# MIMXRT685S_cm33 register map
Vendor: nxp.com; File version: 1.0
CPU: CM33 r2p0, little endian, MPU, FPU, VTOR, 3 interrupt priority bits
Registers are 32-bit, read-write, reset 0x0 unless marked. A register's access mark holds for its fields unless they carry their own. Offsets are from the block's base; [hi:lo] are bit positions; lines under a group give offsets from that group; {n}, {i} and the like mark numbered series; 'fields as' and 'values as' point back to an identical list.

## CLKCTL1 — clock ccontroller 1
Base 0x40021000
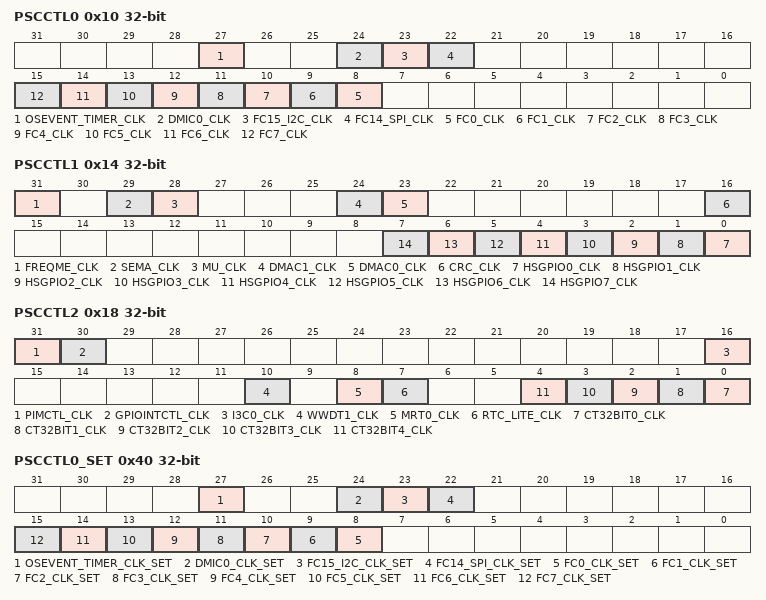
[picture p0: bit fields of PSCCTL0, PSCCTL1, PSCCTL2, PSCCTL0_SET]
0x10 PSCCTL0 — clock control register 0
  [all] fields
    0=DISABLE_CLOCK; 1=ENABLE_CLOCK
  [27] OSEVENT_TIMER_CLK — OS event timer clock control
  [24] DMIC0_CLK — DMIC0 clock control
  [23] FC15_I2C_CLK — flexcomm 15 i2c clock control
  [22] FC14_SPI_CLK — flexcomm 14 spi clock control
  [n+8] FC{n}_CLK (n=0..7) — flexcomm {n} clock control
0x14 PSCCTL1 — clock control register 1
  [all] fields
    0=DISABLE_CLOCK; 1=ENABLE_CLOCK
  [31] FREQME_CLK — FREQME clock control
  [29] SEMA_CLK — SEMA clock control
  [28] MU_CLK — MU clock control
  [24] DMAC1_CLK — DMAC1 clock control
  [23] DMAC0_CLK — DMAC0 clock control
  [16] CRC_CLK — CRC clock control
  [n] HSGPIO{n}_CLK (n=0..7) — HSGPIO{n} clock control
0x18 PSCCTL2 — clock control register 2
  [all] fields
    0=DISABLE_CLOCK; 1=ENABLE_CLOCK
  [31] PIMCTL_CLK — PIMCTL clock control
  [30] GPIOINTCTL_CLK — GPIOINTCTL clock control
  [16] I3C0_CLK — i3c0 clock control
  [10] WWDT1_CLK — wdt1 clock control
  [8] MRT0_CLK — mrt0 clock control
  [7] RTC_LITE_CLK — rtc lite clock control
  [n] CT32BIT{n}_CLK (n=0..4) — ct32bit timer {n} clock control
0x40 PSCCTL0_SET wo reset not defined — clock set register 0
  [all] fields
    0=NO_EFFECT; 1=SET_CLOCK (Sets the PSCCTL0 Bit)
  [27] OSEVENT_TIMER_CLK_SET — OS event timer clock set
  [24] DMIC0_CLK_SET — DMIC0 clock set
  [23] FC15_I2C_CLK_SET — flexcomm 15 i2c clock set
  [22] FC14_SPI_CLK_SET — flexcomm 14 spi clock set
  [n+8] FC{n}_CLK_SET (n=0..7) — flexcomm {n} clock set
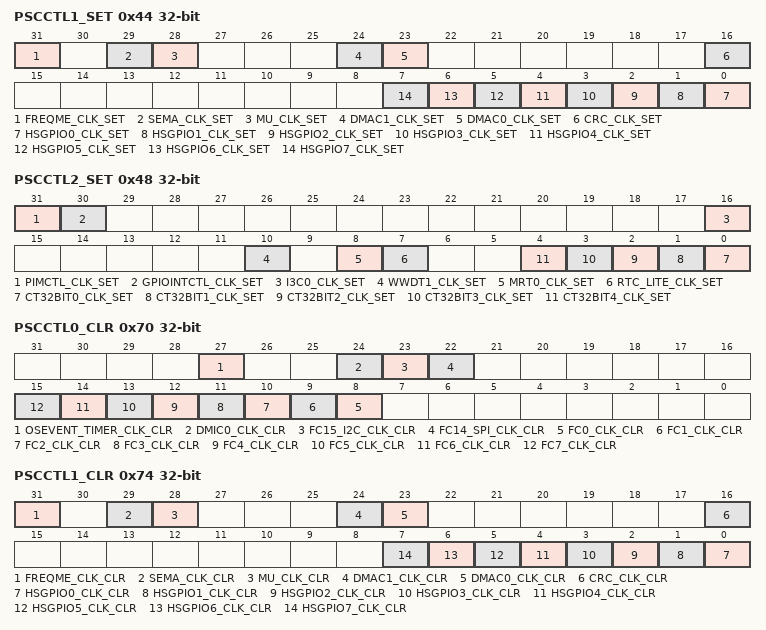
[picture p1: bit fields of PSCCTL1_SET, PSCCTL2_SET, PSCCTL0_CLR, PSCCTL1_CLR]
0x44 PSCCTL1_SET wo reset not defined — clock set register 1
  [all] fields
    0=NO_EFFECT; 1=SET_CLOCK (Sets the PSCCTL1 Bit)
  [31] FREQME_CLK_SET — FREQME clock set
  [29] SEMA_CLK_SET — SEMA clock set
  [28] MU_CLK_SET — MU clock set
  [24] DMAC1_CLK_SET — DMAC1 clock set
  [23] DMAC0_CLK_SET — DMAC0 clock set
  [16] CRC_CLK_SET — CRC clock set
  [n] HSGPIO{n}_CLK_SET (n=0..7) — HSGPIO{n} clock set
0x48 PSCCTL2_SET wo reset not defined — clock set register 2
  [all] fields
    0=NO_EFFECT; 1=SET_CLOCK (Sets the PSCCTL2 Bit)
  [31] PIMCTL_CLK_SET — PIMCTL clock set
  [30] GPIOINTCTL_CLK_SET — GPIOINTCTL clock set
  [16] I3C0_CLK_SET — i3c0 clock set
  [10] WWDT1_CLK_SET — wdt1 clock set
  [8] MRT0_CLK_SET — mrt0 clock set
  [7] RTC_LITE_CLK_SET — rtc lite clock set
  [n] CT32BIT{n}_CLK_SET (n=0..4) — ct32bit timer {n} clock set
0x70 PSCCTL0_CLR wo reset not defined — clock clear register 0
  [all] fields
    0=NO_EFFECT; 1=CLR_CLOCK (Clears the PSCCTL0 Bit)
  [27] OSEVENT_TIMER_CLK_CLR — OS event timer clock clear
  [24] DMIC0_CLK_CLR — DMIC0 clock set
  [23] FC15_I2C_CLK_CLR — flexcomm 15 i2c clock clear
  [22] FC14_SPI_CLK_CLR — flexcomm 14 spi clock clear
  [n+8] FC{n}_CLK_CLR (n=0..7) — flexcomm {n} clock clear
0x74 PSCCTL1_CLR wo reset not defined — clock clear register 1
  [all] fields
    0=NO_EFFECT; 1=CLR_CLOCK (Clears the PSCCTL1 Bit)
  [31] FREQME_CLK_CLR — FREQME clock clear
  [29] SEMA_CLK_CLR — SEMA clock clear
  [28] MU_CLK_CLR — MU clock clear
  [24] DMAC1_CLK_CLR — DMAC1 clock clear
  [23] DMAC0_CLK_CLR — DMAC0 clock clear
  [16] CRC_CLK_CLR — CRC clock clear
  [n] HSGPIO{n}_CLK_CLR (n=0..7) — HSGPIO{n} clock clear
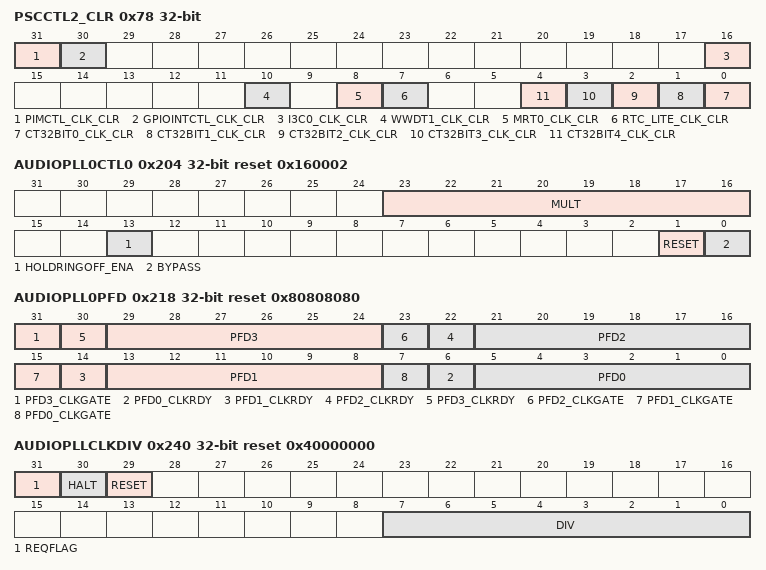
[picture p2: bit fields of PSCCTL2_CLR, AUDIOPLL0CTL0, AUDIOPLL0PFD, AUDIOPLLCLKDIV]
0x78 PSCCTL2_CLR wo reset not defined — clock clear register 2
  [all] fields
    0=NO_EFFECT; 1=CLR_CLOCK (Clears the PSCCTL2 Bit)
  [31] PIMCTL_CLK_CLR — PIMCTL clock clear
  [30] GPIOINTCTL_CLK_CLR — GPIOINTCTL clock clear
  [16] I3C0_CLK_CLR — i3c0 clock clear
  [10] WWDT1_CLK_CLR — wdt1 clock clear
  [8] MRT0_CLK_CLR — mrt0 clock clear
  [7] RTC_LITE_CLK_CLR — rtc lite clock clear
  [n] CT32BIT{n}_CLK_CLR (n=0..4) — ct32bit timer {n} clock clear
0x200 AUDIOPLL0CLKSEL reset 0x7 — audio pll0 clock selection
  [2:0] SEL — System PLL Clock Source Selection. . .
    0=SFRO_CLK (SFRO Clock.); 1=XTAL_CLK (XTALIN Clock.); 2=FFRO_DIV_2 (FFRO Clock Divided by 2.); 7=NONE (None, this may be selected in order to reduce power when no output is needed.)
0x204 AUDIOPLL0CTL0 reset 0x160002 — audio pll0 control0
  [23:16] MULT — Multiplication Factor for FAUDIOPLL0_OUTPUT:
    16=DIV_16; 17=DIV_17; 20=DIV_20; 22=DIV_22; 27=DIV_27; 33=DIV_33
  [13] HOLDRINGOFF_ENA — Hold Ring Off Control
    0=DSIABLE (disbale); 1=ENABLE
  [1] RESET — AUDIOPLL0 Reset:
    0=NORMAL (AUDIOPLL0 reset is removed.); 1=RESET (AUDIOPLL0 is placed into reset.)
  [0] BYPASS — AUDIOPLL0 BYPASS Mode
    0=PROGRAMMED_CLK (PFD output is PFD programmed clock.); 1=BYPASS (PFD output is AUDIOPLL0 reference input clock. (Bypass Mode))
0x20C AUDIOPLL0LOCKTIMEDIV2 reset 0xCAFE — audio pll0 lock time
  [15:0] LOCKTIMEDIV2 — AUDIOPLL0 Lock Time Divide by 2: Programmed lock time is in uS (micro-seconds) and is programmed as half the actual lock time value.
0x210 AUDIOPLL0NUM reset 0x4DD2F15 — audio pll0 number
  [29:0] NUM — This field contains the numerator of the AUDIOPLL0 fractional loop divider. NOTES: 1. The value of numerator must always be configured to be less than the value of the denominator. 2. The AUDIOPLL0NUM register can only be changed when the AUDIOPLL0 is disabled.
0x214 AUDIOPLL0DENOM reset 0x1FFFFFDB
  [29:0] DENOM — This field contains the denominator of the AUDIOPLL0 fractional loop divider. NOTES: 1. The value of numerator must always be configured to be less than the value of the denominator. 2. The AUDIOPLL0DENOM register can only be changed when the AUDIOPLL0 is disabled.
0x218 AUDIOPLL0PFD reset 0x80808080
  [31] PFD3_CLKGATE — PFD3 Clock Gate: 0: PFD3 clock is not gated. 1: PFD3 clock is gated.
    0=NOT_GATED (PFD3 clock is not gated.); 1=GATED (PFD3 clock is gated.)
  [8n+6] PFD{n}_CLKRDY (n=0..3) — PFD{n} Clock Ready Status Flag: Read as 1 clock ready. Cleared by writing a 1.
  [8n+5:8n] PFD{n} (n=0..3) — PLL Fractional Divider {n}: Controls the fractional divider value. Valid PFD values are decimal 12-35.
  [23] PFD2_CLKGATE — PFD2 Clock Gate: 0: PFD2 clock is not gated. 1: PFD2 clock is gated.
    0=NOT_GATED (PFD2 clock is not gated.); 1=GATED (PFD2 clock is gated.)
  [15] PFD1_CLKGATE — PFD1 Clock Gate: 0: PFD1 clock is not gated. 1: PFD1 clock is gated.
    0=NOT_GATED (PFD1 clock is not gated.); 1=GATED (PFD1 clock is gated.)
  [7] PFD0_CLKGATE — PFD0 Clock Gate: 0: PFD0 clock is not gated. 1: PFD0 clock is gated
    0=NOT_GATED (PFD0 clock is not gated.); 1=GATED (PFD0 clock is gated.)
0x240 AUDIOPLLCLKDIV reset 0x40000000 — audio pll0 clock divider
  [31] REQFLAG — Divider status flag. Set when a change is made to the divider value, cleared when the change is complete.
  [30] HALT — Halts the divider counter. The intent is to allow the divider's clock source to be changed without the risk of a glitch at the output.
  [29] RESET — Resets the divider counter. Can be used to make sure a new divider value is used right away rather than completing the previous count.
  [7:0] DIV — Clock Divider Value Selection. . . 0: Divide by 1. ... 255: Divide by 256.
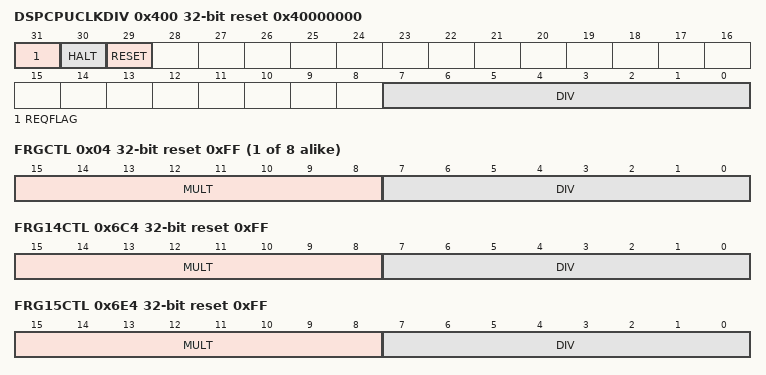
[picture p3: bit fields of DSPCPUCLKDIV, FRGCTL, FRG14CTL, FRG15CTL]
0x400 DSPCPUCLKDIV reset 0x40000000 — DSP cpu clock divider
  fields as AUDIOPLLCLKDIV
0x404 DSPMAINRAMCLKDIV reset 0x1 — DSP main ram clock divider
  [1:0] DSPMRAMCLKDIV — DSP MAINRAM Clock Ratio Control:
    {v}=DSP_CLK_DIV_BY_{v+1} (DSP MAINRAM Clk = DSP Core CLK / {v+1}.) (v=0..3)
0x430 DSPCPUCLKSELA — DSP clock selection A
  [1:0] SEL — Control Main 1st Stage Control Clock Source. . .
    0=FFRO_CLK (FFRO Clock.); 1=XTAL_CLK (XTALIN Clock.); 2=LPOSC (Low Power Oscillator Clock (LPOSC).); 3=SFRO_CLK (SFRO Clock.)
0x434 DSPCPUCLKSELB — DSP clock selection B
  [1:0] SEL — Main Clock Source Selection. . .
    0=MAIN_1ST_CLK (MAINCLKSELA 1st Stage Clock.); 1=MAIN_PLL_CLK (Main System PLL Clock.); 2=DSP_PLL_CLK (DSP System PLL Clock.); 3=RTC_32K_CLK (RTC 32KHz Clock.)
0x480 OSEVENTFCLKSEL (reset mask 0x3) — OS EVENT clock selection
  [2:0] SEL — OS Event Timer Functional Clock Source Selection. . .
    0=LPOSC (Low Power Oscillator Clock (LPOSC).); 1=RTC_32KHZ_CLK (RTC 32KHz Clock.); 2=TEAL_FREE_RUNNING_CLK (Teal Free Running Clock (Global Time Stamping)); 7=NONE (None, this may be selected in order to reduce power when no output is needed.)
{0x500+0x20*i} FLEXCOMM[{i}] (i=0..7) group — flexcomm clock controller
  0x00 FRGCLKSEL reset 0x7 — FRG clock selection register N
    [2:0] SEL — Fractional Gen. Clock Source Selection. . .
      0=MAIN_CLK (Main Clock.); 1=FRG_PLL_CLK (FRG PLL Clock.); 2=SFRO_CLK (SFRO Clock.); 3=FFRO_CLK (FFRO Clock.); 7=NONE (None, this may be selected in order to reduce power when no output is needed.)
  0x04 FRGCTL reset 0xFF — FRG clock controller
    [15:8] MULT — Numerator of the fractional divider. MULT is equal to the programmed value.
    [7:0] DIV — Denominator of the fractional divider. DIV is equal to the programmed value +1. Always set to 0xFF to use with the fractional baud rate generator.
  0x08 FCFCLKSEL reset 0x7 — flexcomm clock selection
    [2:0] SEL — Flexxcomm Functional Clock Source Selection. . .
      0=SFRO_CLK (SFRO Clock.); 1=FFRO_CLK (FFRO Clock.); 2=AUDIO_PLL_CLK (Audio PLL Clock.); 3=MASTER_CLK (Master Clock In.); 4=FCN_FRG_CLK (FCn FRG Clock.); 7=NONE (None, this may be selected in order to reduce power when no output is needed.)
0x6C0 FRG14CLKSEL reset 0x7 — FRG clock selection register 14
  [2:0] SEL — Fractional Gen. Clock Source Selection. . .
    0=MAIN_CLK (Main Clock.); 1=FRG_PLL_CLK (Main System PLL Clock.); 2=SFRO_CLK (SFRO Clock.); 3=FFRO_CLK (FFRO Clock.); 7=NONE (None, this may be selected in order to reduce power when no output is needed.)
0x6C4 FRG14CTL reset 0xFF — FRG clock controller 14
  fields as FLEXCOMM[0].FRGCTL
0x6C8 FC14FCLKSEL reset 0x7 — flexcomm14 clock selection
  fields as FLEXCOMM[0].FCFCLKSEL
0x6E0 FRG15CLKSEL reset 0x7 — FRG clock selection register 15
  fields as FRG14CLKSEL
0x6E4 FRG15CTL reset 0xFF — FRG clock controller 15
  fields as FLEXCOMM[0].FRGCTL
0x6E8 FC15FCLKSEL reset 0x7 — flexcomm15 clock selection
  fields as FLEXCOMM[0].FCFCLKSEL
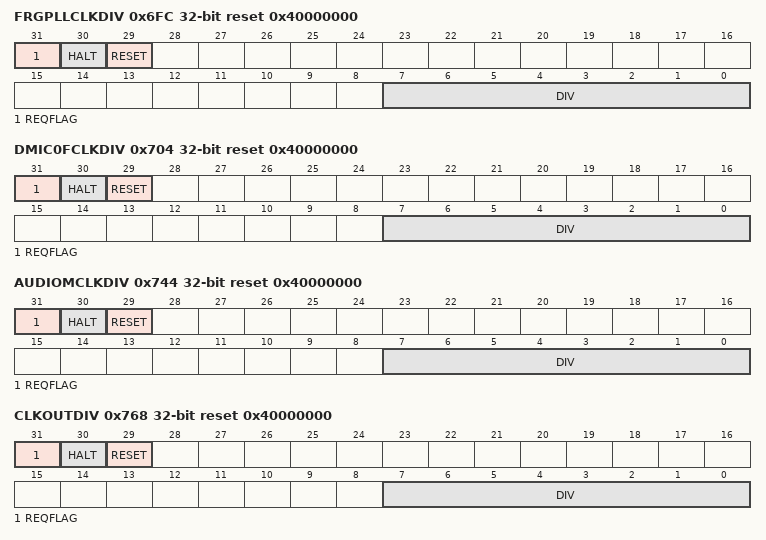
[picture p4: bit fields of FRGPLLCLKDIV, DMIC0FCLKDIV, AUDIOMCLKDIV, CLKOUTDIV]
0x6FC FRGPLLCLKDIV reset 0x40000000 — FRG pll clock divider
  [31] REQFLAG — Divider status flag. Set when a change is made to the divider value, cleared when the change is complete.
  [30] HALT — Halts the divider counter. The intent is to allow the divider clock source to be changed without the risk of a glitch at the output.
  [29] RESET — Resets the divider counter. Can be used to make sure a new divider value is used right away rather than completing the previous count.
  [7:0] DIV — Clock Divider Value Selection. . . 0: Divide by 1. ... 255: Divide by 256.
0x700 DMIC0FCLKSEL reset 0x7 — DMIC0 clk selection
  [2:0] SEL — DMIC Functional Clock Source Selection. . .
    0=SFRO_CLK (SFRO Clock.); 1=FFRO_CLK (FFRO Clock.); 2=AUDIO_PLL_CLK (Audio PLL Clock.); 3=MASTER_CLK (Master Clock In.); 4=LPOSC (Low Power Oscillator Clock (LPOSC).); 5=WAKE_CLK_32KHZ (32KHZ Wake Clk.); 7=NONE (None, this may be selected in order to reduce power when no output is needed.)
0x704 DMIC0FCLKDIV reset 0x40000000 — DMIC clock clock divider
  fields as AUDIOPLLCLKDIV
{0x720+4i} CT32BITFCLKSEL{i} (i=0..4) reset 0x7 — ct32bit timer N clock selection
  [2:0] SEL — CT32Bit Functional Clock Source Selection. . .
    0=MAIN_CLK (Main Clock.); 1=SFRO_CLK (SFRO Clock.); 2=FFRO_CLK (FFRO Clock.); 3=AUDIO_PLL_CLK (Audio PLL Clock.); 4=MASTER_CLK (Master Clock In.); 5=LPOSC (Low Power Oscillator Clock (LPOSC).); 7=NONE (None, this may be selected in order to reduce power when no output is needed.)
0x740 AUDIOMCLKSEL reset 0x7 — audio mclock selection
  [2:0] SEL — Audio MCLK Clock Source Selection. . .
    0=FFRO_CLK (FFRO Clock.); 1=AUDIO_PLL_CLK (AUDIO PLL Clock. (Shared Domain)); 7=NONE (None, this may be selected in order to reduce power when no output is needed.)
0x744 AUDIOMCLKDIV reset 0x40000000 — audio mclock divider
  fields as AUDIOPLLCLKDIV
0x760 CLKOUTSEL0 reset 0x7 — clock out selection 0
  [2:0] SEL — Clock Output Select 1st Stage. . .
    0=SFRO_CLK (SFRO Clock.); 1=XTALIN_CLK (XTALIN Clock.); 2=LPOSC (Low Power Oscillator Clock (LPOSC).); 3=FFRO_CLK (FFRO Clock.); 4=MAIN_CLK (Main Clock.); 6=DSP_MAIN_CLK (DSP Main Clock.); 7=NONE (None, this may be selected in order to reduce power when no output is needed.)
0x764 CLKOUTSEL1 reset 0x7 — clock out selection 1
  [2:0] SEL — Clock out clock Source Selection. . .
    0=CLKOUTSEL0_OUTPUT (CLKOUTSEL0 Multiplexed Output.); 1=MAIN_PLL_CLK (Main System PLL Clock.); 2=SYSPLL0_AUX0_PLL_CLK (SYSPLL0 AUX0_PLL_Clock.); 3=DSP_PLL_CLK (DSP PLL clock.); 4=SYSPLL0_AUX1_PLL_CLK (SYSPLL0 AUX1_PLL_Clock.); 5=AUDIO_PLL_CLK (AUDIO PLL Clock.); 6=RTC_CLK_32KHZ (32KHz RTC Clock.); 7=NONE (None, this may be selected in order to reduce power when no output is needed.)
0x768 CLKOUTDIV reset 0x40000000 — clock_out divider
  fields as AUDIOPLLCLKDIV
0x780 I3C0FCLKSEL reset 0x7 — I3C0 fclk selection
  [2:0] SEL — I3C0 FClock Source Selection. . .
    0=MAIN_CLK (Main Clock.); 1=FFRO_CLK (FFRO Clock.); 7=NONE (None, this may be selected in order to reduce power when no output is needed.)
0x784 I3C0FCLKSTCSEL reset 0x7 — I3C0 fclk STC selection
  [2:0] SEL — I3C0 Clock Source Selection. . .
    0=I3C0_FCLK_SELECTION; 1=LPOSC (Low Power Oscillator Clock (LPOSC).); 7=NONE (None, this may be selected in order to reduce power when no output is needed.)
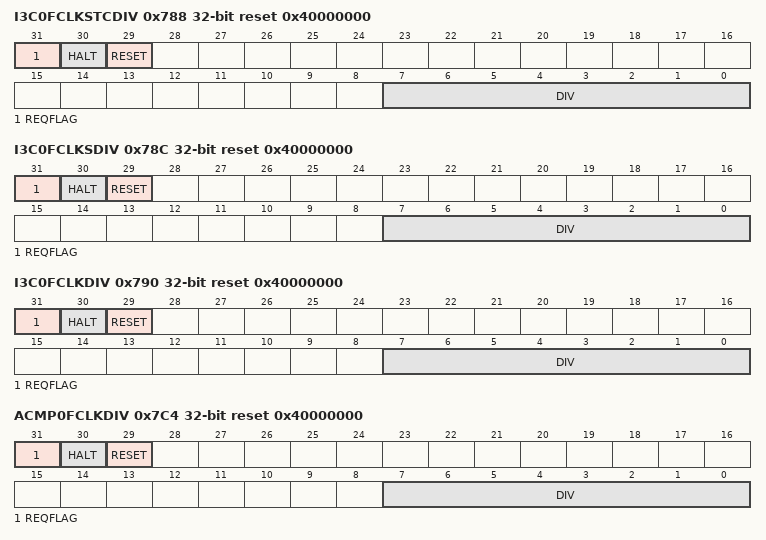
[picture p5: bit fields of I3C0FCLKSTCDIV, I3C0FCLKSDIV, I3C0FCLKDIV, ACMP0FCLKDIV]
0x788 I3C0FCLKSTCDIV reset 0x40000000 — I3C0 fclk STC divider
  fields as AUDIOPLLCLKDIV
0x78C I3C0FCLKSDIV reset 0x40000000 — I3C0 fclks divider
  fields as FRGPLLCLKDIV
0x790 I3C0FCLKDIV reset 0x40000000 — I3C0 fclk divider
  fields as FRGPLLCLKDIV
0x7A0 WDT1FCLKSEL — WDT1 clock selection
  [2:0] SEL — WDT1 Functional Clock Source Selection. . .
    0=LPOSC (Low Power Oscillator Clock (LPOSC).); 7=NONE (None, this may be selected in order to reduce power when no output is needed.)
0x7C0 ACMP0FCLKSEL reset 0x7 — acomparator 0 clock selection
  [2:0] SEL — ACMP0 Fast Functional Clock Source Selection. . .
    0=MAIN_CLK (Main Clock.); 1=SFRO_CLK (SFRO Clock.); 2=FFRO_CLK (FFRO Clock.); 3=SYSPLL0_AUX0_PLL_CLK (SYSPLL0 AUX0_PLL_Clock.); 4=SYSPLL0_AUX1_PLL_CLK (SYSPLL0 AUX1_PLL_Clock.); 7=NONE (None, this may be selected in order to reduce power when no output is needed.)
0x7C4 ACMP0FCLKDIV reset 0x40000000 — acomparator 0 fclk divider
  fields as FRGPLLCLKDIV
